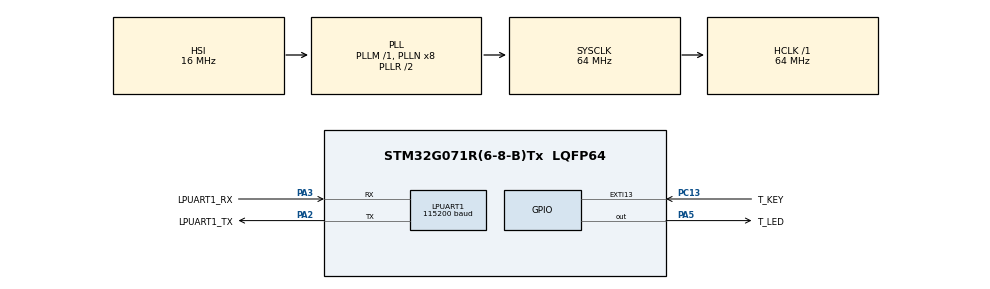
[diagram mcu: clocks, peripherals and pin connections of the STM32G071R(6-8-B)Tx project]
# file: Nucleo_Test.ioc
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LPUART1.BaudRate=115200
Mcu.Family=STM32G0
Mcu.Name=STM32G071R(6-8-B)Tx
Mcu.Package=LQFP64
NVIC.EXTI4_15_IRQn=true\:2\:0\:true\:false\:true\:true
NVIC.USART3_4_LPUART1_IRQn=true\:1\:0\:true\:false\:true\:true
PA13.GPIO_Label=TMS
PA13.Mode=Serial_Wire
PA13.Signal=SYS_SWDIO
PA14-BOOT0.GPIO_Label=TCK
PA14-BOOT0.Mode=Serial_Wire
PA14-BOOT0.Signal=SYS_SWCLK
PA2.GPIO_Label=LPUART1_TX
PA2.Mode=Asynchronous
PA2.Signal=LPUART1_TX
PA3.GPIO_Label=LPUART1_RX
PA3.Mode=Asynchronous
PA3.Signal=LPUART1_RX
PA5.GPIO_Label=T_LED
PA5.Signal=GPIO_Output
PC13.GPIO_Label=T_KEY
PC13.GPIO_ModeDefaultEXTI=GPIO_MODE_IT_FALLING
PC13.GPIO_PuPd=GPIO_PULLUP
PC13.Signal=GPXTI13
PC14-OSC32_IN\ (PC14).Mode=LSE-External-Oscillator
PC14-OSC32_IN\ (PC14).Signal=RCC_OSC32_IN
PC15-OSC32_OUT\ (PC15).Mode=LSE-External-Oscillator
PC15-OSC32_OUT\ (PC15).Signal=RCC_OSC32_OUT
ProjectManager.HeapSize=0x200
ProjectManager.StackSize=0x400
ProjectManager.TargetToolchain=MDK-ARM V5
RCC.ADCFreq_Value=64000000
RCC.AHBFreq_Value=64000000
RCC.CortexFreq_Value=64000000
RCC.EXTERNAL_CLOCK_VALUE=12288000
RCC.HCLKFreq_Value=64000000
RCC.HSE_VALUE=8000000
RCC.HSI_VALUE=16000000
RCC.SYSCLKFreq_VALUE=64000000
RCC.SYSCLKSource=RCC_SYSCLKSOURCE_PLLCLK
RCC.VCOOutputFreq_Value=128000000
board=NUCLEO-G071RB

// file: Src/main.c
/* USER CODE BEGIN Header */
/**
  ******************************************************************************
  * @file           : main.c
  * @brief          : Main program body
  ******************************************************************************
  ** This notice applies to any and all portions of this file
  * that are not between comment pairs USER CODE BEGIN and
  * USER CODE END. Other portions of this file, whether
  * inserted by the user or by software development tools
  * are owned by their respective copyright owners.
  *
  * COPYRIGHT(c) 2019 STMicroelectronics
  *
  * Redistribution and use in source and binary forms, with or without modification,
  * are permitted provided that the following conditions are met:
  *   1. Redistributions of source code must retain the above copyright notice,
  *      this list of conditions and the following disclaimer.
  *   2. Redistributions in binary form must reproduce the above copyright notice,
  *      this list of conditions and the following disclaimer in the documentation
  *      and/or other materials provided with the distribution.
  *   3. Neither the name of STMicroelectronics nor the names of its contributors
  *      may be used to endorse or promote products derived from this software
  *      without specific prior written permission.
  *
  * THIS SOFTWARE IS PROVIDED BY THE COPYRIGHT HOLDERS AND CONTRIBUTORS "AS IS"
  * AND ANY EXPRESS OR IMPLIED WARRANTIES, INCLUDING, BUT NOT LIMITED TO, THE
  * IMPLIED WARRANTIES OF MERCHANTABILITY AND FITNESS FOR A PARTICULAR PURPOSE ARE
  * DISCLAIMED. IN NO EVENT SHALL THE COPYRIGHT HOLDER OR CONTRIBUTORS BE LIABLE
  * FOR ANY DIRECT, INDIRECT, INCIDENTAL, SPECIAL, EXEMPLARY, OR CONSEQUENTIAL
  * DAMAGES (INCLUDING, BUT NOT LIMITED TO, PROCUREMENT OF SUBSTITUTE GOODS OR
  * SERVICES; LOSS OF USE, DATA, OR PROFITS; OR BUSINESS INTERRUPTION) HOWEVER
  * CAUSED AND ON ANY THEORY OF LIABILITY, WHETHER IN CONTRACT, STRICT LIABILITY,
  * OR TORT (INCLUDING NEGLIGENCE OR OTHERWISE) ARISING IN ANY WAY OUT OF THE USE
  * OF THIS SOFTWARE, EVEN IF ADVISED OF THE POSSIBILITY OF SUCH DAMAGE.
  *
  ******************************************************************************
  */
/* USER CODE END Header */

#include "main.h"
#include "usart.h"
#include "gpio.h"

/* USER CODE BEGIN Includes */
#include "Resource.h"
#include "pwr.h"
/* USER CODE END Includes */

/* USER CODE BEGIN PV */
extern UART_HandleTypeDef hlpuart1;
/* USER CODE END PV */

void SystemClock_Config(void);

/* USER CODE BEGIN 0 */
uint8_t Gpio_Wakeup_Flag = 0;
/* USER CODE END 0 */

int main(void)
{
    HAL_Init();
    SystemClock_Config();

    MX_GPIO_Init();

    MX_LPUART1_UART_Init();

    LED_Blinking_5s();//LED显示
    PRINTF("This is Test\r\n");

    //准备进入低功耗模式
    ///HAL_UART_MspDeInit(&hlpuart1);//关掉UART
	  __HAL_UART_DISABLE(&hlpuart1);
    HAL_GPIO_DeInit(GPIOA, LPUART1_TX_Pin | LPUART1_RX_Pin);//关掉UART,不要用MspDeinit，只DeInitGpio就可以

    HAL_GPIO_WritePin(T_LED_GPIO_Port, T_LED_Pin, GPIO_PIN_RESET);//关闭之前在使用，睡眠模式不需要的GPIO

    MX_PWR_GPIO_Init();           //关掉所有GPIO为模拟输入

    //MX_PWR_SystemClock_Init();    //关掉无关的时钟，注意当Hse或HSI作为系统时钟或者使能PLL到的时候，不能关闭HSE||HSI

    MX_PWR_Init(STOP1, PWR_STOPENTRY_WFI);//进入低功耗模式
    //MX_PWR_Init(STOP0, PWR_STOPENTRY_WFI);
    //
    //。。。。进入低功耗模式

    //退出低功耗模式
    SystemClock_Config();
    //MX_PWR_SystemClock_fromSTOP();
    HAL_GPIO_DeInit(T_LED_GPIO_Port, T_LED_Pin);

    //HAL_UART_MspDeInit(&hlpuart1);

    MX_GPIO_Init();
    LED_Blinking_5s();
    //HAL_GPIO_TogglePin(T_LED_GPIO_Port, T_LED_Pin);
    //MX_LPUART1_UART_Init();

    UART_Out_Stop(&hlpuart1);
		 __HAL_UART_ENABLE(&hlpuart1);
    //UART_SendByte(&hlpuart1,0x79);
    PRINTF("This is Wakeup Event\r\n");

    while (1)
    {
        /* USER CODE END WHILE */

        /* USER CODE BEGIN 3 */
        if (Gpio_Wakeup_Flag == 1)
        {
            Gpio_Wakeup_Flag = 0;

        }

    }
    /* USER CODE END 3 */
}

void SystemClock_Config(void)
{
    RCC_OscInitTypeDef RCC_OscInitStruct = {0};
    RCC_ClkInitTypeDef RCC_ClkInitStruct = {0};

    /**Configure the main internal regulator output voltage
    */
    HAL_PWREx_ControlVoltageScaling(PWR_REGULATOR_VOLTAGE_SCALE1);

    /**Initializes the CPU, AHB and APB busses clocks
    */
    RCC_OscInitStruct.OscillatorType = RCC_OSCILLATORTYPE_HSI;
    RCC_OscInitStruct.HSIState = RCC_HSI_ON;
    RCC_OscInitStruct.HSIDiv = RCC_HSI_DIV1;
    RCC_OscInitStruct.HSICalibrationValue = RCC_HSICALIBRATION_DEFAULT;
    RCC_OscInitStruct.PLL.PLLState = RCC_PLL_ON;
    RCC_OscInitStruct.PLL.PLLSource = RCC_PLLSOURCE_HSI;
    RCC_OscInitStruct.PLL.PLLM = RCC_PLLM_DIV1;
    RCC_OscInitStruct.PLL.PLLN = 8;
    RCC_OscInitStruct.PLL.PLLP = RCC_PLLP_DIV2;
    RCC_OscInitStruct.PLL.PLLQ = RCC_PLLQ_DIV2;
    RCC_OscInitStruct.PLL.PLLR = RCC_PLLR_DIV2;
    if (HAL_RCC_OscConfig(&RCC_OscInitStruct) != HAL_OK)
    {
        Error_Handler();
    }
    /**Initializes the CPU, AHB and APB busses clocks
    */
    RCC_ClkInitStruct.ClockType = RCC_CLOCKTYPE_HCLK | RCC_CLOCKTYPE_SYSCLK
                                  | RCC_CLOCKTYPE_PCLK1;
    RCC_ClkInitStruct.SYSCLKSource = RCC_SYSCLKSOURCE_PLLCLK;
    RCC_ClkInitStruct.AHBCLKDivider = RCC_SYSCLK_DIV1;
    RCC_ClkInitStruct.APB1CLKDivider = RCC_HCLK_DIV1;

    if (HAL_RCC_ClockConfig(&RCC_ClkInitStruct, FLASH_LATENCY_2) != HAL_OK)
    {
        Error_Handler();
    }

}

/* USER CODE BEGIN 4 */
void HAL_GPIO_EXTI_Falling_Callback(uint16_t GPIO_Pin)
{
    if(GPIO_Pin == GPIO_PIN_13)
    {
        Gpio_Wakeup_Flag = 1;
    }
}
/* USER CODE END 4 */

void Error_Handler(void)
{
    while(1)
    {
    }
}

/************************ (C) COPYRIGHT STMicroelectronics *****END OF FILE****/
